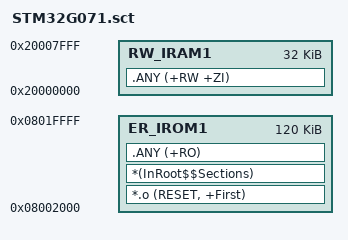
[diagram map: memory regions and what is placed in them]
; *************************************************************
; *** Scatter-Loading Description File generated by uVision ***
; *************************************************************
; First 8kb in ROM is reserved for the OpenBLT bootloader
LR_IROM1 0x08002000 0x0001E000  {    ; load region size_region
  ER_IROM1 0x08002000 0x0001E000  {  ; load address = execution address
   *.o (RESET, +First)
   *(InRoot$$Sections)
   .ANY (+RO)
  }
  RW_IRAM1 0x20000000 0x00008000  {  ; RW data
   .ANY (+RW +ZI)
  }
}

